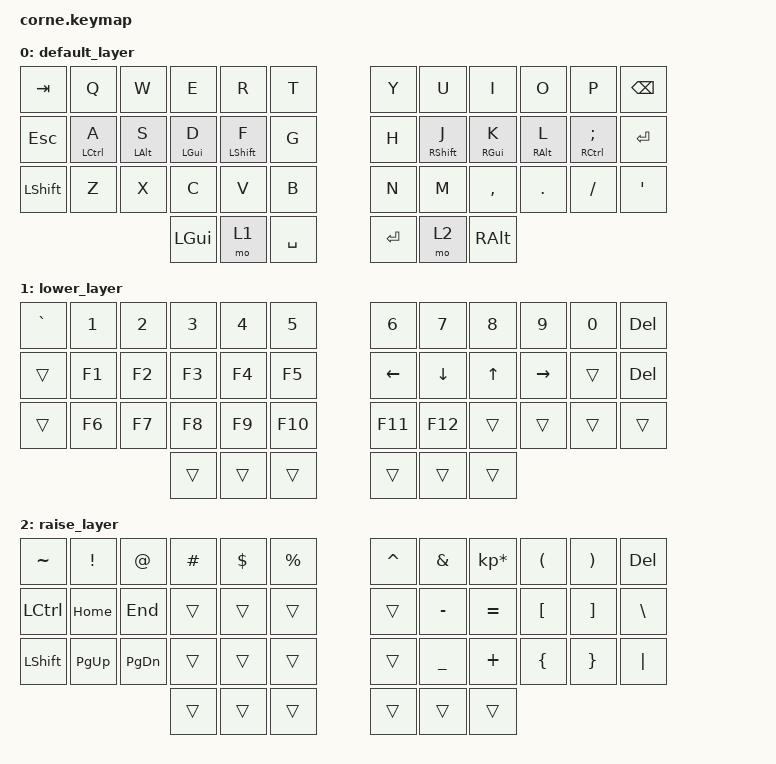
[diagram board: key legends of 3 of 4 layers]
/*
 * Copyright (c) 2020 The ZMK Contributors
 *
 * SPDX-License-Identifier: MIT
 */

#include <behaviors.dtsi>
#include <dt-bindings/zmk/keys.h>
#include <dt-bindings/zmk/bt.h>
#include <dt-bindings/zmk/rgb.h>
#include <dt-bindings/zmk/backlight.h>
#include <dt-bindings/led/led.h>

/ {
    conditional_layers {
        compatible = "zmk,conditional-layers";
        adjust_layer {
            if-layers = <1 2>;
            then-layer = <3>;
        };
    };

    behaviors {
        bhm: balanced_homerow_mods {
            compatible = "zmk,behavior-hold-tap";
            label = "HOMEROW_MODS";
            #binding-cells = <2>;
            tapping-term-ms = <200>;    // <---[[moderate duration]]
						quick-tap-ms = <0>;
						#global-quick-tap;
            flavor = "balanced";
            bindings = <&kp>, <&kp>;
        };
        hm: homerow_mods {
            compatible = "zmk,behavior-hold-tap";
            label = "HOMEROW_MODS";
            #binding-cells = <2>;
            tapping-term-ms = <150>;
            quick-tap-ms = <0>;
            flavor = "tap-preferred";
            bindings = <&kp>, <&kp>;
        };
    };

        keymap {
                compatible = "zmk,keymap";

                default_layer {
// -----------------------------------------------------------------------------------------
// |  TAB |  Q  |  W  |  E  |  R  |  T  |   |  Y  |  U   |  I  |  O  |  P  | BKSP |
// |  ESC |  A  |  S  |  D  |  F  |  G  |   |  H  |  J   |  K  |  L  |  ;  | ENT  |
// | SHFT |  Z  |  X  |  C  |  V  |  B  |   |  N  |  M   |  ,  |  .  |  /  |  '   |
//                    | GUI | LWR | SPC |   | ENT | RSE  | ALT |
                        bindings = <
   &kp TAB   &kp Q        &kp W       &kp E       &kp R         &kp T   &kp Y &kp U          &kp I       &kp O        &kp P           &kp BSPC
   &kp ESC   &bhm LCTRL A &bhm LALT S &bhm LGUI D &bhm LSHIFT F &kp G   &kp H &hm RSHIFT J   &hm RGUI K  &hm RALT L   &hm RCTRL SEMI  &kp RET
   &kp LSHFT &kp Z        &kp X       &kp C       &kp V         &kp B   &kp N &kp M          &kp COMMA   &kp DOT      &kp FSLH        &kp SQT
                          &kp LGUI    &mo 1       &kp SPACE                   &kp RET        &mo 2       &kp RALT
                        >;
                };

                lower_layer {
// -----------------------------------------------------------------------------------------
// |   `  |  1  |  2  |  3  |  4  |  5  |   |  6  |  7  |  8  |  9  |  0  | DEL  |
// |      | F1  | F2  | F3  | F4  | F5  |   | LFT | DWN |  UP | RGT |     |      |
// |      | F6  | F7  | F8  | F9  | F10 |   |     |     |     |     |     |      |
//                    |     |     |     |   |     |     |     |
                        bindings = <
   &kp GRAVE    &kp N1       &kp N2       &kp N3       &kp N4       &kp N5   &kp N6   &kp N7   &kp N8 &kp N9    &kp N0  &kp DEL
   &trans       &kp F1       &kp F2       &kp F3       &kp F4       &kp F5   &kp LEFT &kp DOWN &kp UP &kp RIGHT &trans  &kp DEL
   &trans       &kp F6       &kp F7       &kp F8       &kp F9       &kp F10  &kp F11  &kp F12  &trans &trans    &trans  &trans
                          	        &trans     &trans       &trans      &trans  &trans   &trans
                        >;
                };

                raise_layer {
// -----------------------------------------------------------------------------------------
// | TILDE|  !  |  @  |  #  |  $  |  %  |   |  ^  |  &  |  *  |  (  |  )  | DEL  |
// | CTRL | HOME| END |     |     |     |   |     |  -  |  =  |  [  |  ]  |  \   |
// | SHFT | PGU | PGD |     |     |     |   |     |  _  |  +  |  {  |  }  | "|"  |
//                    |     |     |     |   |     |     |     |     |
                        bindings = <
   &kp TILDE &kp EXCL   &kp AT     &kp HASH &kp DLLR &kp PRCNT   &kp CARET &kp AMPS  &kp KP_MULTIPLY &kp LPAR &kp RPAR &kp DEL
   &kp LCTRL &kp HOME   &kp END    &trans   &trans   &trans      &trans    &kp MINUS &kp EQUAL       &kp LBKT &kp RBKT &kp BSLH
   &kp LSHFT &kp PG_UP  &kp PG_DN  &trans   &trans   &trans      &trans    &kp UNDER &kp PLUS        &kp LBRC &kp RBRC &kp PIPE
                    	     &trans &trans   &trans   &trans   &trans    &trans
                        >;
                };

                adjust_layer {
// -----------------------------------------------------------------------------------------
// | BTCLR| BT1 | BT2 | BT3 | BT4 | BT5 |   |     |     |     |     |     |      |
// | BL   | RGB |     |     |     |     |   |     |     |     |     |     |      |
// |      |     |     |     |     |     |   |     |     |     |     |     |      |
//                    |     |     |     |   |     |     |     |
                        bindings = <
   &bt BT_CLR &bt BT_SEL 0    &bt BT_SEL 1    &bt BT_SEL 2    &bt BT_SEL 3       &bt BT_SEL 4   &trans &trans &trans &trans &trans &trans
   &bl BL_TOG &rgb_ug RGB_TOG &rgb_ug RGB_EFF &rgb_ug RGB_BRI &rgb_ug RGB_BRD    &trans         &trans &trans &trans &trans &trans &trans
   &trans     &trans       &trans       &trans       &trans       &trans         &trans         &trans &trans &trans &trans &trans &trans
                    	                  &trans       &trans       &trans         &trans &trans &trans
                        >;
                };

        };
};

